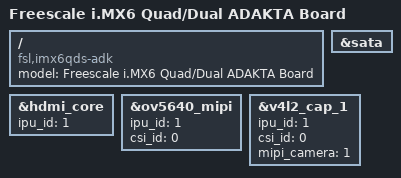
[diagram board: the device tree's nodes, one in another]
/*
 * Copyright 2017 Adakta, Inc.
 * Copyright 2013-2016 Boundary Devices, Inc.
 * Copyright 2012 Freescale Semiconductor, Inc.
 * Copyright 2011 Linaro Ltd.
 *
 * The code contained herein is licensed under the GNU General Public
 * License. You may obtain a copy of the GNU General Public License
 * Version 2 or later at the following locations:
 *
 * http://www.opensource.org/licenses/gpl-license.html
 * http://www.gnu.org/copyleft/gpl.html
 */

/dts-v1/;

#include <dt-bindings/interrupt-controller/irq.h>
#include "imx6q.dtsi"
#include "imx6qd-adakta_adk.dtsi"

/ {
	model = "Freescale i.MX6 Quad/Dual ADAKTA Board";
	compatible = "fsl,imx6qds-adk", "fsl,imx6q";
};


&hdmi_core {
	ipu_id = <1>;
};

&ov5640_mipi {
	ipu_id = <1>;
	csi_id = <0>;
};

&sata {
	status = "okay";
};

/* ov5640_mipi */
&v4l2_cap_1 {
	ipu_id = <1>;
	csi_id = <0>;
	mipi_camera = <1>;
};
